VERSION "HIPBNYYYYYYYYYYYYYYYYYYYYYYYYYYYYYYYYYYYYY/4/%%%/4/'%**4YYY///"

NS_ :

BS_:

BU_: ME_AWS_CANA
VAL_TABLE_ Vt_RGB 3 "blue" 2 "green" 1 "red" 0 "off" ;
VAL_TABLE_ Vt_ON_OFF 1 "on" 0 "off" ;

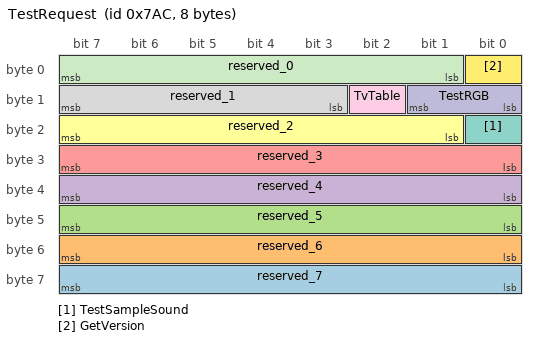
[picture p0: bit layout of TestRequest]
BO_ 1964 TestRequest: 8 ME_AWS_CANA
 SG_ reserved_7 : 56|8@1+ (1,0) [255|255] "" Vector__XXX
 SG_ reserved_6 : 48|8@1+ (1,0) [255|255] "" Vector__XXX
 SG_ reserved_5 : 40|8@1+ (1,0) [255|255] "" Vector__XXX
 SG_ reserved_4 : 32|8@1+ (1,0) [255|255] "" Vector__XXX
 SG_ reserved_3 : 24|8@1+ (1,0) [255|255] "" Vector__XXX
 SG_ reserved_2 : 17|7@1+ (1,0) [127|127] "" Vector__XXX
 SG_ TestSampleSound : 16|1@1+ (1,0) [0|1] "" Vector__XXX
 SG_ reserved_1 : 11|5@1+ (1,0) [31|31] "" Vector__XXX
 SG_ TvTable : 10|1@1+ (1,0) [0|1] "" Vector__XXX
 SG_ TestRGB : 8|2@1+ (1,0) [0|3] "" Vector__XXX
 SG_ reserved_0 : 1|7@1+ (1,0) [127|127] "" Vector__XXX
 SG_ GetVersion : 0|1@1+ (1,0) [0|1] "" Vector__XXX

VAL_ 1964 TvTable 1 "on" 0 "off" ;
VAL_ 1964 TestRGB 3 "blue" 2 "green" 1 "red" 0 "off" ;
VAL_ 1964 GetVersion 1 "on" 0 "off" ;
